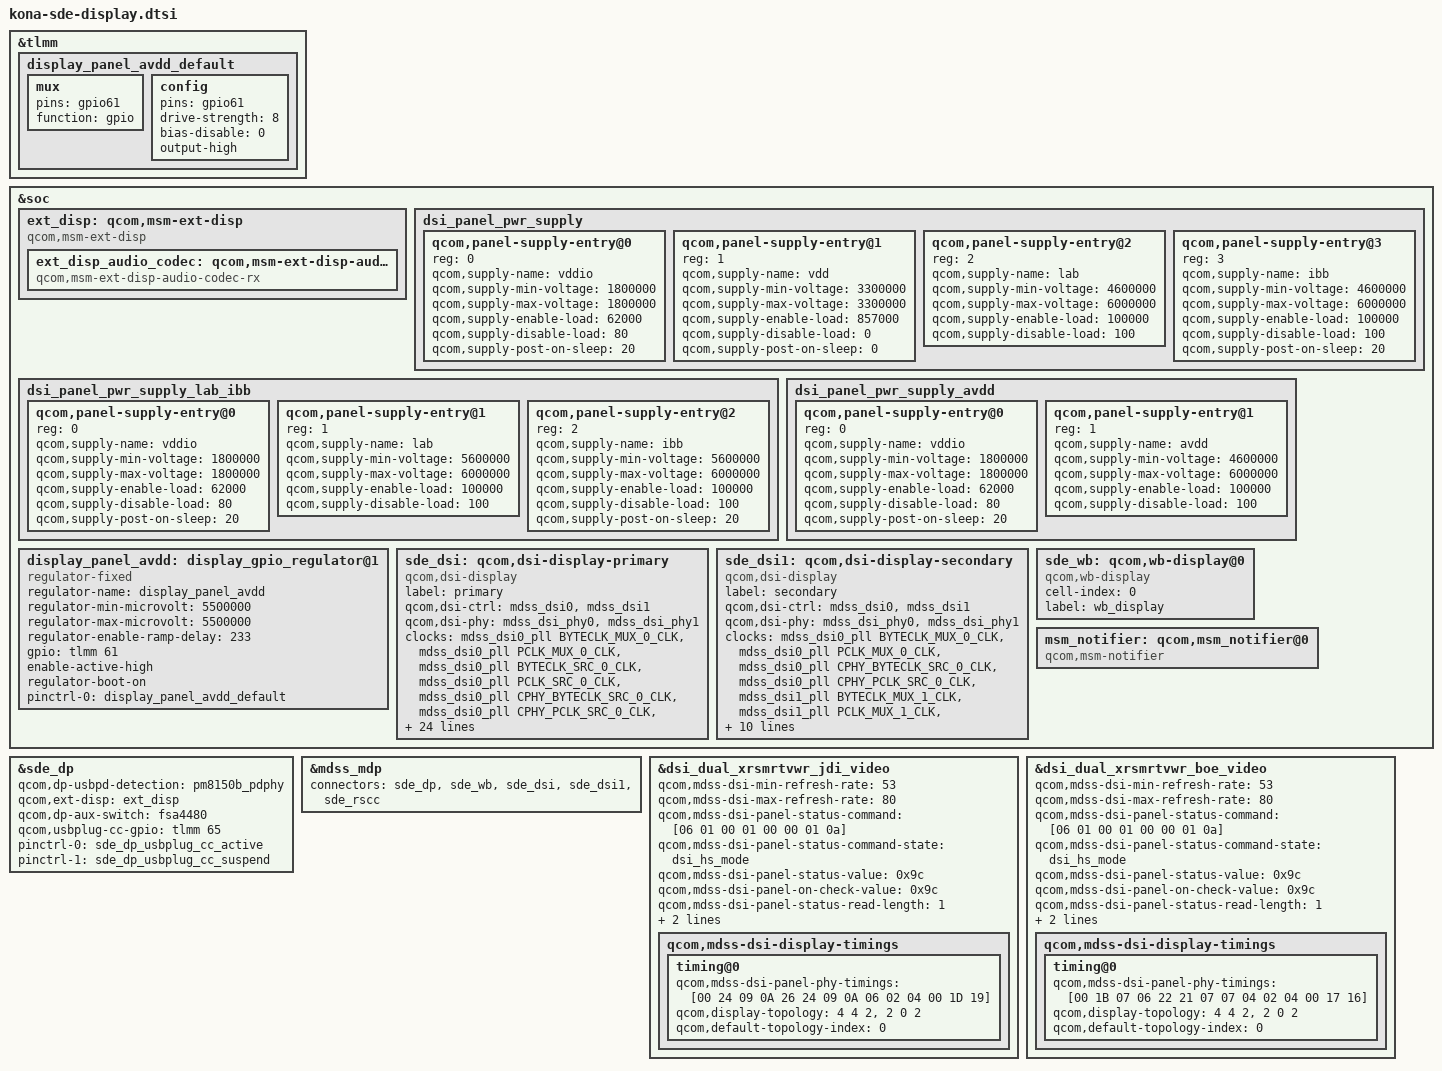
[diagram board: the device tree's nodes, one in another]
#include "display/dsi-panel-xrsmrtvwr-boe-dual-video.dtsi"
#include "display/dsi-panel-xrsmrtvwr-jdi-dual-video.dtsi"
#include <dt-bindings/clock/mdss-7nm-pll-clk.h>

&tlmm {
	display_panel_avdd_default: display_panel_avdd_default {
		mux {
			pins = "gpio61";
			function = "gpio";
		};

		config {
			pins = "gpio61";
			drive-strength = <8>;
			bias-disable = <0>;
			output-high;
		};
	};
};

&soc {
	ext_disp: qcom,msm-ext-disp {
		compatible = "qcom,msm-ext-disp";

		ext_disp_audio_codec: qcom,msm-ext-disp-audio-codec-rx {
			compatible = "qcom,msm-ext-disp-audio-codec-rx";
		};
	};

	dsi_panel_pwr_supply: dsi_panel_pwr_supply {
		#address-cells = <1>;
		#size-cells = <0>;

		qcom,panel-supply-entry@0 {
			reg = <0>;
			qcom,supply-name = "vddio";
			qcom,supply-min-voltage = <1800000>;
			qcom,supply-max-voltage = <1800000>;
			qcom,supply-enable-load = <62000>;
			qcom,supply-disable-load = <80>;
			qcom,supply-post-on-sleep = <20>;
		};

		qcom,panel-supply-entry@1 {
			reg = <1>;
			qcom,supply-name = "vdd";
			qcom,supply-min-voltage = <3300000>;
			qcom,supply-max-voltage = <3300000>;
			qcom,supply-enable-load = <857000>;
			qcom,supply-disable-load = <0>;
			qcom,supply-post-on-sleep = <0>;
		};

		qcom,panel-supply-entry@2 {
			reg = <2>;
			qcom,supply-name = "lab";
			qcom,supply-min-voltage = <4600000>;
			qcom,supply-max-voltage = <6000000>;
			qcom,supply-enable-load = <100000>;
			qcom,supply-disable-load = <100>;
		};

		qcom,panel-supply-entry@3 {
			reg = <3>;
			qcom,supply-name = "ibb";
			qcom,supply-min-voltage = <4600000>;
			qcom,supply-max-voltage = <6000000>;
			qcom,supply-enable-load = <100000>;
			qcom,supply-disable-load = <100>;
			qcom,supply-post-on-sleep = <20>;
		};
	};

	dsi_panel_pwr_supply_lab_ibb: dsi_panel_pwr_supply_lab_ibb {
		#address-cells = <1>;
		#size-cells = <0>;

		qcom,panel-supply-entry@0 {
			reg = <0>;
			qcom,supply-name = "vddio";
			qcom,supply-min-voltage = <1800000>;
			qcom,supply-max-voltage = <1800000>;
			qcom,supply-enable-load = <62000>;
			qcom,supply-disable-load = <80>;
			qcom,supply-post-on-sleep = <20>;
		};

		qcom,panel-supply-entry@1 {
			reg = <1>;
			qcom,supply-name = "lab";
			qcom,supply-min-voltage = <5600000>;
			qcom,supply-max-voltage = <6000000>;
			qcom,supply-enable-load = <100000>;
			qcom,supply-disable-load = <100>;
		};

		qcom,panel-supply-entry@2 {
			reg = <2>;
			qcom,supply-name = "ibb";
			qcom,supply-min-voltage = <5600000>;
			qcom,supply-max-voltage = <6000000>;
			qcom,supply-enable-load = <100000>;
			qcom,supply-disable-load = <100>;
			qcom,supply-post-on-sleep = <20>;
		};
	};

	dsi_panel_pwr_supply_avdd: dsi_panel_pwr_supply_avdd {
		#address-cells = <1>;
		#size-cells = <0>;

		qcom,panel-supply-entry@0 {
			reg = <0>;
			qcom,supply-name = "vddio";
			qcom,supply-min-voltage = <1800000>;
			qcom,supply-max-voltage = <1800000>;
			qcom,supply-enable-load = <62000>;
			qcom,supply-disable-load = <80>;
			qcom,supply-post-on-sleep = <20>;
		};

		qcom,panel-supply-entry@1 {
			reg = <1>;
			qcom,supply-name = "avdd";
			qcom,supply-min-voltage = <4600000>;
			qcom,supply-max-voltage = <6000000>;
			qcom,supply-enable-load = <100000>;
			qcom,supply-disable-load = <100>;
		};
	};

	display_panel_avdd: display_gpio_regulator@1 {
		compatible = "regulator-fixed";
		regulator-name = "display_panel_avdd";
		regulator-min-microvolt = <5500000>;
		regulator-max-microvolt = <5500000>;
		regulator-enable-ramp-delay = <233>;
		gpio = <&tlmm 61 0>;
		enable-active-high;
		regulator-boot-on;
		pinctrl-names = "default";
		pinctrl-0 = <&display_panel_avdd_default>;
	};

	sde_dsi: qcom,dsi-display-primary {
		compatible = "qcom,dsi-display";
		label = "primary";

		qcom,dsi-ctrl = <&mdss_dsi0 &mdss_dsi1>;
		qcom,dsi-phy = <&mdss_dsi_phy0 &mdss_dsi_phy1>;

		clocks = <&mdss_dsi0_pll BYTECLK_MUX_0_CLK>,
			 <&mdss_dsi0_pll PCLK_MUX_0_CLK>,
			 <&mdss_dsi0_pll BYTECLK_SRC_0_CLK>,
			 <&mdss_dsi0_pll PCLK_SRC_0_CLK>,
			 <&mdss_dsi0_pll CPHY_BYTECLK_SRC_0_CLK>,
			 <&mdss_dsi0_pll CPHY_PCLK_SRC_0_CLK>,
			 <&mdss_dsi0_pll SHADOW_BYTECLK_SRC_0_CLK>,
			 <&mdss_dsi0_pll SHADOW_PCLK_SRC_0_CLK>,
			 <&mdss_dsi0_pll SHADOW_CPHY_BYTECLK_SRC_0_CLK>,
			 <&mdss_dsi0_pll SHADOW_CPHY_PCLK_SRC_0_CLK>,
			 <&mdss_dsi1_pll BYTECLK_MUX_1_CLK>,
			 <&mdss_dsi1_pll PCLK_MUX_1_CLK>,
			 <&mdss_dsi1_pll BYTECLK_SRC_1_CLK>,
			 <&mdss_dsi1_pll PCLK_SRC_1_CLK>,
			 <&mdss_dsi1_pll CPHY_BYTECLK_SRC_1_CLK>,
			 <&mdss_dsi1_pll CPHY_PCLK_SRC_1_CLK>,
			 <&mdss_dsi1_pll SHADOW_BYTECLK_SRC_1_CLK>,
			 <&mdss_dsi1_pll SHADOW_PCLK_SRC_1_CLK>,
			 <&mdss_dsi1_pll SHADOW_CPHY_BYTECLK_SRC_1_CLK>,
			 <&mdss_dsi1_pll SHADOW_CPHY_PCLK_SRC_1_CLK>;

		clock-names = "mux_byte_clk0", "mux_pixel_clk0",
				"src_byte_clk0", "src_pixel_clk0",
				"cphy_byte_clk0", "cphy_pixel_clk0",
				"shadow_byte_clk0", "shadow_pixel_clk0",
				"shadow_cphybyte_clk0", "shadow_cphypixel_clk0",
				"mux_byte_clk1", "mux_pixel_clk1",
				"src_byte_clk1", "src_pixel_clk1",
				"cphy_byte_clk1", "cphy_pixel_clk1",
				"shadow_byte_clk1", "shadow_pixel_clk1",
				"shadow_cphybyte_clk1", "shadow_cphypixel_clk1";

		pinctrl-names = "panel_active", "panel_suspend";
		pinctrl-0 = <&sde_dsi_active &sde_te_active>;
		pinctrl-1 = <&sde_dsi_suspend &sde_te_suspend>;

		qcom,platform-te-gpio = <&tlmm 66 0>;
		qcom,panel-te-source = <0>;

		vddio-supply = <&pm8150_l14>;
		vdd-supply = <&pm8150a_l11>;
		avdd-supply = <&display_panel_avdd>;
		lab-supply = <&ab_vreg>;
		ibb-supply = <&ibb_vreg>;

		qcom,mdp = <&mdss_mdp>;
	};

	sde_dsi1: qcom,dsi-display-secondary {
		compatible = "qcom,dsi-display";
		label = "secondary";

		qcom,dsi-ctrl = <&mdss_dsi0 &mdss_dsi1>;
		qcom,dsi-phy = <&mdss_dsi_phy0 &mdss_dsi_phy1>;

		clocks = <&mdss_dsi0_pll BYTECLK_MUX_0_CLK>,
			 <&mdss_dsi0_pll PCLK_MUX_0_CLK>,
			 <&mdss_dsi0_pll CPHY_BYTECLK_SRC_0_CLK>,
			 <&mdss_dsi0_pll CPHY_PCLK_SRC_0_CLK>,
			 <&mdss_dsi1_pll BYTECLK_MUX_1_CLK>,
			 <&mdss_dsi1_pll PCLK_MUX_1_CLK>,
			 <&mdss_dsi1_pll CPHY_BYTECLK_SRC_1_CLK>,
			 <&mdss_dsi1_pll CPHY_PCLK_SRC_1_CLK>;
		clock-names = "mux_byte_clk0", "mux_pixel_clk0",
			      "cphy_byte_clk0", "cphy_pixel_clk0",
			      "mux_byte_clk1", "mux_pixel_clk1",
			      "cphy_byte_clk1", "cphy_pixel_clk1";

		pinctrl-names = "panel_active", "panel_suspend";
		pinctrl-0 = <&sde_dsi1_active &sde_te1_active>;
		pinctrl-1 = <&sde_dsi1_suspend &sde_te1_suspend>;

		qcom,platform-te-gpio = <&tlmm 67 0>;
		qcom,panel-te-source = <1>;

		vddio-supply = <&pm8150_l14>;
		vdd-supply = <&pm8150a_l11>;
		avdd-supply = <&display_panel_avdd>;

		qcom,mdp = <&mdss_mdp>;
	};

	sde_wb: qcom,wb-display@0 {
		compatible = "qcom,wb-display";
		cell-index = <0>;
		label = "wb_display";
	};

	msm_notifier: qcom,msm_notifier@0 {
		compatible = "qcom,msm-notifier";
	};
};

&sde_dp {
	qcom,dp-usbpd-detection = <&pm8150b_pdphy>;
	qcom,ext-disp = <&ext_disp>;
	qcom,dp-aux-switch = <&fsa4480>;

	qcom,usbplug-cc-gpio = <&tlmm 65 0>;

	pinctrl-names = "mdss_dp_active", "mdss_dp_sleep";
	pinctrl-0 = <&sde_dp_usbplug_cc_active>;
	pinctrl-1 = <&sde_dp_usbplug_cc_suspend>;
};

&mdss_mdp {
	connectors = <&sde_dp &sde_wb &sde_dsi &sde_dsi1 &sde_rscc>;
};

&dsi_dual_xrsmrtvwr_jdi_video {
	qcom,mdss-dsi-min-refresh-rate = <53>;
	qcom,mdss-dsi-max-refresh-rate = <80>;
	qcom,mdss-dsi-panel-status-command = [06 01 00 01 00 00 01 0a];
	qcom,mdss-dsi-panel-status-command-state = "dsi_hs_mode";
	qcom,mdss-dsi-panel-status-value = <0x9c>;
	qcom,mdss-dsi-panel-on-check-value = <0x9c>;
	qcom,mdss-dsi-panel-status-read-length = <1>;
	qcom,dsi-select-clocks = "mux_byte_clk0", "mux_pixel_clk0";
	qcom,mdss-dsi-display-timings {
		timing@0 {
			/* 1:2DSC 90Hz */
			qcom,mdss-dsi-panel-phy-timings = [00 24 09 0A 26 24 09
				0A 06 02 04 00 1D 19];
			/* noDSC 60Hz */
			/* qcom,mdss-dsi-panel-phy-timings = [00 21 08 08 25 23 09
				08 06 02 04 00 1B 18]; */
			qcom,display-topology = <4 4 2>,
						<2 0 2>;
			qcom,default-topology-index = <0>;
		};
	};
};

&dsi_dual_xrsmrtvwr_boe_video {
	qcom,mdss-dsi-min-refresh-rate = <53>;
	qcom,mdss-dsi-max-refresh-rate = <80>;
	qcom,mdss-dsi-panel-status-command = [06 01 00 01 00 00 01 0a];
	qcom,mdss-dsi-panel-status-command-state = "dsi_hs_mode";
	qcom,mdss-dsi-panel-status-value = <0x9c>;
	qcom,mdss-dsi-panel-on-check-value = <0x9c>;
	qcom,mdss-dsi-panel-status-read-length = <1>;
	qcom,dsi-select-clocks = "mux_byte_clk0", "mux_pixel_clk0";
	qcom,mdss-dsi-display-timings {
		timing@0 {
			/* 1:2DSC 90Hz */
			qcom,mdss-dsi-panel-phy-timings = [00 1B 07 06 22 21 07
				07 04 02 04 00 17 16];
			/* noDSC 50Hz */
			/*qcom,mdss-dsi-panel-phy-timings = [00 1F 08 08 24 22 08
				08 05 02 04 00 1A 18]; */
			qcom,display-topology = <4 4 2>,
						<2 0 2>;
			qcom,default-topology-index = <0>;
		};
	};
};
